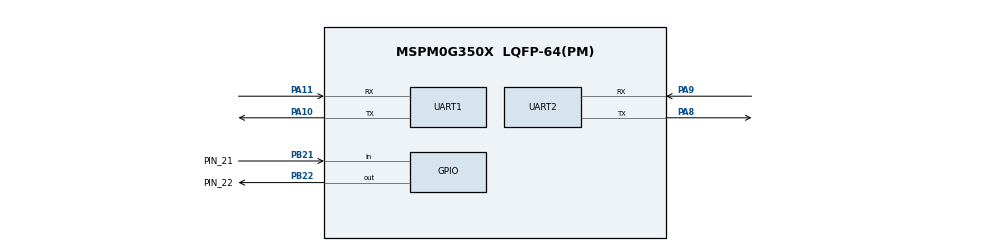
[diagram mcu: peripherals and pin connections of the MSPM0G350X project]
/**
 * @cliArgs --device "MSPM0G350X" --part "Default" --package "LQFP-64(PM)" --product "mspm0_sdk@2.10.00.04"
 * @versions {"tool":"1.26.2+4477"}
 */
const GPIO   = scripting.addModule("/ti/driverlib/GPIO", {}, false);
const LED    = GPIO.addInstance();
const KEYIN  = GPIO.addInstance();
const UART   = scripting.addModule("/ti/driverlib/UART", {}, false);
const UART1  = UART.addInstance();
const UART2  = UART.addInstance();
const SYSCTL = scripting.addModule("/ti/driverlib/SYSCTL");

UART1.$name                      = "UART_0";
UART1.profile                    = "CONFIG_PROFILE_1";
UART1.peripheral.$assign         = "UART0";
UART1.targetBaudRate             = 115200;
UART1.enableInternalLoopback     = false;
UART1.enabledInterrupts          = ["RX"];
UART1.enableFIFO                 = false;
UART1.peripheral.rxPin.$assign   = "PA11";
UART1.peripheral.txPin.$assign   = "PA10";

UART2.$name                      = "UART_1";
UART2.profile                    = "CONFIG_PROFILE_1";
UART2.peripheral.$assign         = "UART1";
UART2.targetBaudRate             = 115200;
UART2.enableInternalLoopback     = false;
UART2.enabledInterrupts          = ["RX"];
UART2.enableFIFO                 = false;
UART2.peripheral.rxPin.$assign   = "PA9";
UART2.peripheral.txPin.$assign   = "PA8";

LED.$name                         = "LED1";
LED.associatedPins[0].$name       = "PIN_22";
LED.associatedPins[0].pin.$assign = "PB22";

KEYIN.$name                              = "KEY";
KEYIN.associatedPins[0].$name            = "PIN_21";
KEYIN.associatedPins[0].direction        = "INPUT";
KEYIN.associatedPins[0].internalResistor = "PULL_UP";
KEYIN.associatedPins[0].pin.$assign      = "PB21";
const Board = scripting.addModule("/ti/driverlib/Board", {}, false);

SYSCTL.forceDefaultClkConfig = true;
Board.peripheral.$suggestSolution          = "DEBUGSS";
Board.peripheral.swclkPin.$suggestSolution = "PA20";
Board.peripheral.swdioPin.$suggestSolution = "PA19";
SYSCTL.peripheral.$suggestSolution         = "SYSCTL";
